BU_: OBC

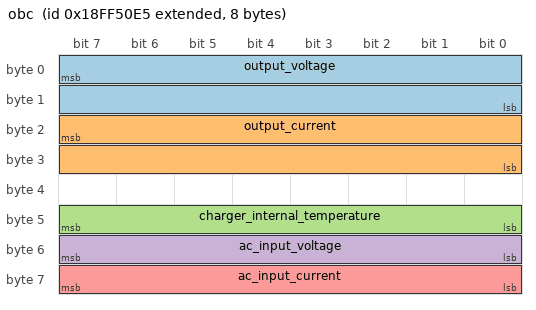
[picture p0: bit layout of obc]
BO_ 2566869221 obc: 8 OBC
 SG_ output_voltage : 7|16@0+ (0.1,0) [0|8031.875] "V" Vector__XXX
 SG_ output_current : 23|16@0+ (0.1,0) [0|0] "A" Vector__XXX
 SG_ charger_internal_temperature : 40|8@1+ (1,-100) [0|100] "" OBC
 SG_ ac_input_voltage : 48|8@1+ (2,0) [0|100] "" OBC
 SG_ ac_input_current : 56|8@1+ (0.1,0) [0|100] "" OBC
